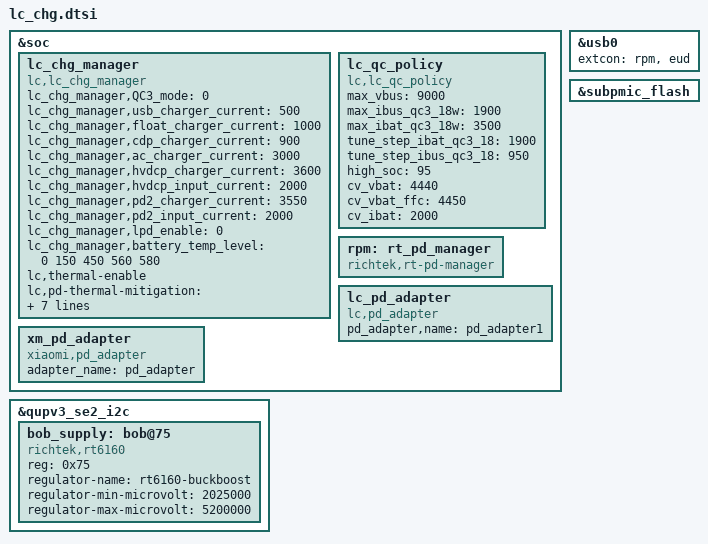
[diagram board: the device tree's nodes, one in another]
#include "subpmic.dtsi"
#include "tcpc.dtsi"
#include "sm5602_fg.dtsi"
#include "battery_secret.dtsi"

&soc {
	lc_chg_manager:lc_chg_manager {
		compatible = "lc,lc_chg_manager";
		#io-channel-cells = <1>;
		status = "ok";
		lc_chg_manager,QC3_mode = <0>; /*0-not support; 1-QC3; 2-QC3P5*/
		lc_chg_manager,usb_charger_current = <500>;
		lc_chg_manager,float_charger_current = <1000>;
		lc_chg_manager,cdp_charger_current = <900>;
		lc_chg_manager,ac_charger_current = <3000>;
		lc_chg_manager,hvdcp_charger_current = <3600>;
		lc_chg_manager,hvdcp_input_current = <2000>;
		//lc_chg_manager,hvdcp3_charger_current = <4000>;
		//lc_chg_manager,hvdcp3_input_current = <3000>;
		lc_chg_manager,pd2_charger_current = <3550>;
		lc_chg_manager,pd2_input_current = <2000>;
		lc_chg_manager,lpd_enable = <0>;
		//chargerpump,master;
		lc_chg_manager,battery_temp_level = <0 150 450 560 580>;
		lc,thermal-enable;
		lc,pd-thermal-mitigation = <3600 3400 3000 2800 2600
									2200 2000 1800 1600 1400
									1200 1000 900 700 500
									300>;
		lc,pd-thermal-mitigation-fast = <3600 3400 3000 2800 2600
									2200 2000 1800 1600 1400
									1200 1000 900 700 500
									300>;
		lc,qc2-thermal-mitigation = <3600 3400 3000 2800 2600
									2200 2000 1800 1600 1400
									1200 1000 900 700 500
									300>;
		lc_chg_manager,cyclecount = <100 300 800 65535>;

		lc_chg_manager,dropfv = <0 20 20 40>;
	};
/*
	lc_cp_policy:lc_cp_policy {
		compatible = "lc,lc_cp_policy";
		#io-channel-cells = <1>;
		status = "ok";
	};
*/
	lc_qc_policy:lc_qc_policy {
		compatible = "lc,lc_qc_policy";
		#io-channel-cells = <1>;
		status = "ok";
		max_vbus = <9000>;
		max_ibus_qc3_18w = <1900>;
		max_ibat_qc3_18w = <3500>;
		//max_ibus_qc3_27w = <3000>;
		//max_ibat_qc3_27w = <5400>;
		//max_ibus_qc35 = <2250>;
		//max_ibat_qc35 = <4400>;
		//tune_step_ibat_qc3_27 = <2000>;
		tune_step_ibat_qc3_18 = <1900>;
		//tune_step_ibat_qc35 = <200>;
		//tune_step_ibus_qc3_27 = <1000>;
		tune_step_ibus_qc3_18 = <950>;
		//tune_step_ibus_qc35 = <50>;
		high_soc = <95>;
		cv_vbat = <4440>;
		cv_vbat_ffc = <4450>;
		cv_ibat = <2000>;
	};

	rpm: rt_pd_manager {
		compatible = "richtek,rt-pd-manager";
		#io-channel-cells = <1>;
		status = "ok";
	};

	lc_pd_adapter: lc_pd_adapter {
		compatible = "lc,pd_adapter";
		status = "ok";
		pd_adapter,name = "pd_adapter1";
		#io-channel-cells = <1>;
	};

	xm_pd_adapter:xm_pd_adapter {
		compatible = "xiaomi,pd_adapter";
		status = "ok";
		adapter_name = "pd_adapter";
		#io-channel-cells = <1>;
	};
};

&usb0 {
	extcon = <&rpm>, <&eud>;
};

&subpmic_flash {
	status = "ok";
};

&qupv3_se2_i2c {
	bob_supply: bob@75 {
		compatible = "richtek,rt6160";
		reg = <0x75>;
		regulator-name = "rt6160-buckboost";
		regulator-min-microvolt = <2025000>;
		regulator-max-microvolt = <5200000>;
	};
};

#include "lc_jeita.dtsi"
